# STM32U535 register map
File version: 1.0
CPU: CM33 r0p1, little endian, MPU, FPU, 4 interrupt priority bits
Registers are 32-bit, read-write, reset 0x0 unless marked. A register's access mark holds for its fields unless they carry their own. Offsets are from the block's base; [hi:lo] are bit positions; {n}, {i} and the like mark numbered series.

## TIM15 — General purpose timers
Base 0x40014000
Same registers: SEC_TIM15 0x50014000
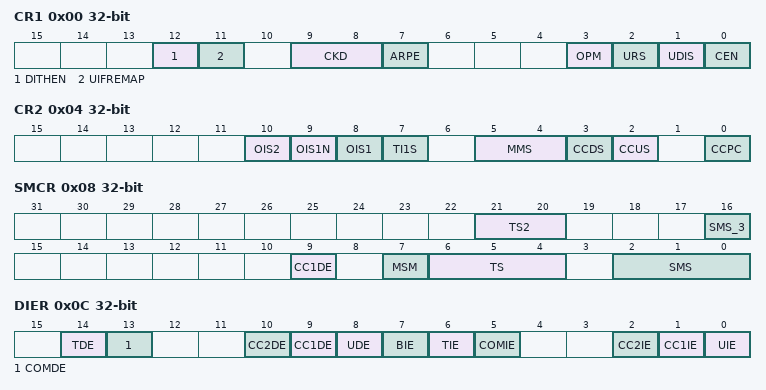
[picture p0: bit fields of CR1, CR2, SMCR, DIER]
0x00 CR1 — control register 1
  [12] DITHEN — Dithering enable
    0=Disabled (Dithering disabled); 1=Enabled (Dithering enabled)
  [11] UIFREMAP — UIF status bit remapping
    0=Disabled (No remapping. UIF status bit is not copied to TIMx_CNT register bit 31); 1=Enabled (Remapping enabled. UIF status bit is copied to TIMx_CNT register bit 31)
  [9:8] CKD — Clock division
    0=Div1 (t_DTS = t_CK_INT); 1=Div2 (t_DTS = 2 × t_CK_INT); 2=Div4 (t_DTS = 4 × t_CK_INT)
  [7] ARPE — Auto-reload preload enable
    0=Disabled (TIMx_APRR register is not buffered); 1=Enabled (TIMx_APRR register is buffered)
  [3] OPM — One-pulse mode
    0=Disabled (Counter is not stopped at update event); 1=Enabled (Counter stops counting at the next update event (clearing the CEN bit))
  [2] URS — Update request source
    0=AnyEvent (Any of counter overflow/underflow, setting UG, or update through slave mode, generates an update interrupt or DMA request); 1=CounterOnly (Only counter overflow/underflow generates an update interrupt or DMA request)
  [1] UDIS — Update disable
    0=Enabled (Update event enabled); 1=Disabled (Update event disabled)
  [0] CEN — Counter enable
    0=Disabled (Counter disabled); 1=Enabled (Counter enabled)
0x04 CR2 — control register 2
  [n+8] OIS{n}N (n=1..1) — Output Idle state (OC{n}N output)
    0=Reset (OCxN=0 after a dead-time when MOE=0); 1=Set (OCxN=1 after a dead-time when MOE=0)
  [2n+6] OIS{n} (n=1..2) — Output Idle state (OC{n} output)
    0=Reset (OCx=0 (after a dead-time if OCx(N) is implemented) when MOE=0); 1=Set (OCx=1 (after a dead-time if OCx(N) is implemented) when MOE=0)
  [7] TI1S — TI1 selection
  [5:4] MMS — Master mode selection
  [3] CCDS — Capture/compare DMA selection
    0=OnCompare (CCx DMA request sent when CCx event occurs); 1=OnUpdate (CCx DMA request sent when update event occurs)
  [2] CCUS — Capture/compare control update selection
    0=Sw (When capture/compare control bits are preloaded (CCPC=1), they are updated by setting the COMG bit only); 1=SwOrEdge (When capture/compare control bits are preloaded (CCPC=1), they are updated by setting the COMG bit or when an rising edge occurs on TRGI)
  [0] CCPC — Capture/compare preloaded control
    0=NotPreloaded (CCxE, CCxNE and OCxM bits are not preloaded); 1=Preloaded (CCxE, CCxNE and OCxM bits are preloaded)
0x08 SMCR — slave mode control register
  [21:20] TS2 — Trigger selection
  [16] SMS_3 — Slave mode selection
  [9] CC1DE — Capture/Compare 1 DMA request enable
  [7] MSM — Master/slave mode
  [6:4] TS — Trigger selection
  [2:0] SMS — Slave mode selection
0x0C DIER — DMA/Interrupt enable register
  [14] TDE — Trigger DMA request enable
    0=Disabled (Trigger DMA request disabled); 1=Enabled (Trigger DMA request enabled)
  [13] COMDE — COM DMA request enable
    0=Disabled (COM DMA request disabled); 1=Enabled (COM DMA request enabled)
  [n+8] CC{n}DE (n=1..2) — Capture/Compare {n} DMA request enable
    0=Disabled (CCx DMA request disabled); 1=Enabled (CCx DMA request enabled)
  [8] UDE — Update DMA request enable
    0=Disabled (Update DMA request disabled); 1=Enabled (Update DMA request enabled)
  [7] BIE — Break interrupt enable
    0=Disabled (Break interrupt disabled); 1=Enabled (Break interrupt enabled)
  [6] TIE — Trigger interrupt enable
    0=Disabled (Trigger interrupt disabled); 1=Enabled (Trigger interrupt enabled)
  [5] COMIE — COM interrupt enable
    0=Disabled (COM interrupt disabled); 1=Enabled (COM interrupt enabled)
  [n] CC{n}IE (n=1..2) — Capture/Compare {n} interrupt enable
    0=Disabled (CCx interrupt disabled); 1=Enabled (CCx interrupt enabled)
  [0] UIE — Update interrupt enable
    0=Disabled (Update interrupt disabled); 1=Enabled (Update interrupt enabled)
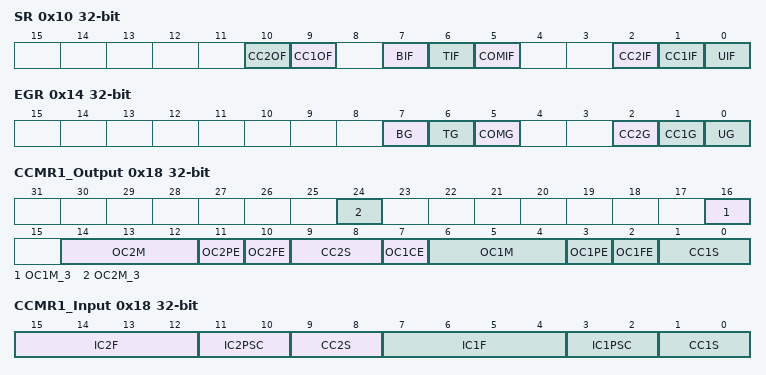
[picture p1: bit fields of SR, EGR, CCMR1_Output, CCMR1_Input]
0x10 SR — status register
  [n+8] CC{n}OF (n=1..2) write-0-clears — Capture/Compare {n} overcapture flag
    on read: 0=No overcapture has been detected; 1=Overcapture (The counter value has been captured in TIMx_CCRx register while CCxIF flag was already set) | on write: 0=Clear flag
  [7] BIF write-0-clears — Break interrupt flag
    on read: 0=NoTrigger (No break event occurred); 1=Trigger (An active level has been detected on the break input. An interrupt is generated if BIE=1 in the TIMx_DIER register) | on write: 0=Clear flag
  [6] TIF write-0-clears — Trigger interrupt flag
    on read: 0=No trigger event occurred; 1=Trigger interrupt pending | on write: 0=Clear flag
  [5] COMIF write-0-clears — COM interrupt flag
    on read: 0=No COM event occurred; 1=COM (COM interrupt pending) | on write: 0=Clear flag
  [n] CC{n}IF (n=1..2) write-0-clears — Capture/compare {n} interrupt flag
    on read: 0=NoMatch (No campture/compare has been detected); 1=Match (If CC1 is an output: The content of the counter TIMx_CNT matches the content of the TIMx_CCR1 register. If CC1 is an input: The counter value has been captured in TIMx_CCR1 register.) | on write: 0=Clear flag
  [0] UIF write-0-clears — Update interrupt flag
    on read: 0=NoUpdateOccurred; 1=UpdatePending (Update interrupt pending) | on write: 0=Clear flag
0x14 EGR access per field — event generation register
  [7] BG wo — Break generation
    1=Trigger (A break event is generated. MOE bit is cleared and BIF flag is set. Related interrupt or DMA transfer can occur if enabled)
  [6] TG wo — Trigger generation
    1=Trigger (The TIF flag is set in TIMx_SR register. Related interrupt or DMA transfer can occur if enabled.)
  [5] COMG rw — Capture/Compare control update generation
    on write: 1=Trigger (When CCPC bit is set, it allows CCxE, CCxNE and OCxM bits to be updated)
  [n] CC{n}G (n=1..2) wo — Capture/compare {n} generation
    1=Trigger (If CC1 is an output: CC1IF flag is set, Corresponding interrupt or DMA request is sent if enabled. If CC1 is an input: The current value of the counter is captured in TIMx_CCR1 register.)
  [0] UG wo — Update generation
    1=Update (Re-initializes the timer counter and generates an update of the registers.)
0x18 CCMR1_Output — capture/compare mode register (output mode)
  [8n+8] OC{n}M_3 (n=1..2) — Output compare {n} mode, bit 3
    0=Normal output compare mode (modes 0-7); 1=Extended output compare mode (modes 7-15)
  [n+6] OC{n}CE (n=1..1) — Output compare {n} clear enable
    0=Disabled (OCxRef is not affected by the ocref_clr_int signal); 1=Enabled (OCxRef is cleared as soon as a High level is detected on ocref_clr_int signal)
  [8n-2:8n-4] OC{n}M (n=1..2) — Output compare {n} mode
    0=Frozen (The comparison between the output compare register TIMx_CCRy and the counter TIMx_CNT has no effect on the outputs / OpmMode1: Retriggerable OPM mode 1 - In up-counting mode, the channel is active until a trigger event is detected (on TRGI signal). In down-counting mode, the channel is inactive); 1=ActiveOnMatch (Set channel to active level on match. OCyREF signal is forced high when the counter matches the capture/compare register / OpmMode2: Inversely to OpmMode1); 2=InactiveOnMatch (Set channel to inactive level on match. OCyREF signal is forced low when the counter matches the capture/compare register / Reserved); 3=Toggle (OCyREF toggles when TIMx_CNT=TIMx_CCRy / Reserved); 4=ForceInactive (OCyREF is forced low / CombinedPwmMode1: OCyREF has the same behavior as in PWM mode 1. OCyREFC is the logical OR between OC1REF and OC2REF); 5=ForceActive (OCyREF is forced high / CombinedPwmMode2: OCyREF has the same behavior as in PWM mode 2. OCyREFC is the logical AND between OC1REF and OC2REF); 6=PwmMode1 (In upcounting, channel is active as long as TIMx_CNT<TIMx_CCRy else inactive. In downcounting, channel is inactive as long as TIMx_CNT>TIMx_CCRy else active / Reserved); 7=PwmMode2 (Inversely to PwmMode1 / Reserved)
  [8n-5] OC{n}PE (n=1..2) — Output compare {n} preload enable
    0=Disabled (Preload register on CCRx disabled. New values written to CCRx are taken into account immediately); 1=Enabled (Preload register on CCRx enabled. Preload value is loaded into active register on each update event)
  [8n-6] OC{n}FE (n=1..2) — Output compare {n} fast enable
    0=Disabled (Fast output disabled); 1=Enabled (Fast output enabled)
  [8n-7:8n-8] CC{n}S (n=1..2) — Capture/Compare {n} selection
    0=Output (CCx channel is configured as output)
0x18 CCMR1_Input (alternate view of CCMR1_Output) — capture/compare mode register 1 (input mode)
  [9:8] CC2S — Capture/Compare 2 selection
    1=TI2 (CC2 channel is configured as input, IC2 is mapped on TI2); 2=TI1 (CC2 channel is configured as input, IC2 is mapped on TI1); 3=TRC (CC2 channel is configured as input, IC2 is mapped on TRC)
  [8n-1:8n-4] IC{n}F (n=1..2) — Input capture {n} filter
    0=No filter, sampling is done at fDTS; 1=FCK_INT_N2 (fSAMPLING=fCK_INT, N=2); 2=FCK_INT_N4 (fSAMPLING=fCK_INT, N=4); 3=FCK_INT_N8 (fSAMPLING=fCK_INT, N=8); 4=FDTS_Div2_N6 (fSAMPLING=fDTS/2, N=6); 5=FDTS_Div2_N8 (fSAMPLING=fDTS/2, N=8); 6=FDTS_Div4_N6 (fSAMPLING=fDTS/4, N=6); 7=FDTS_Div4_N8 (fSAMPLING=fDTS/4, N=8); 8=FDTS_Div8_N6 (fSAMPLING=fDTS/8, N=6); 9=FDTS_Div8_N8 (fSAMPLING=fDTS/8, N=8); 10=FDTS_Div16_N5 (fSAMPLING=fDTS/16, N=5); 11=FDTS_Div16_N6 (fSAMPLING=fDTS/16, N=6); 12=FDTS_Div16_N8 (fSAMPLING=fDTS/16, N=8); 13=FDTS_Div32_N5 (fSAMPLING=fDTS/32, N=5); 14=FDTS_Div32_N6 (fSAMPLING=fDTS/32, N=6); 15=FDTS_Div32_N8 (fSAMPLING=fDTS/32, N=8)
  [8n-5:8n-6] IC{n}PSC (n=1..2) — Input capture {n} prescaler
    0=No prescaler, capture is done each time an edge is detected on the capture input; 1=TwoEvents (Capture is done once every 2 events); 2=FourEvents (Capture is done once every 4 events); 3=EightEvents (Capture is done once every 8 events)
  [1:0] CC1S — Capture/Compare 1 selection
    1=TI1 (CC1 channel is configured as input, IC1 is mapped on TI1); 2=TI2 (CC1 channel is configured as input, IC1 is mapped on TI2); 3=TRC (CC1 channel is configured as input, IC1 is mapped on TRC)
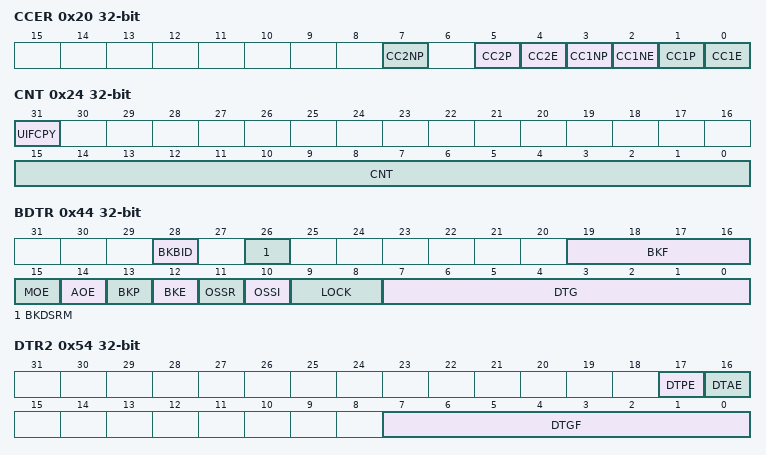
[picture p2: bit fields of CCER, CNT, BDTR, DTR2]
0x20 CCER — capture/compare enable register
  [4n-1] CC{n}NP (n=1..2) — Capture/Compare {n} output Polarity
    0=ActiveHigh (OCxN active high); 1=ActiveLow (OCxN active low)
  [n+1] CC{n}NE (n=1..1) — Capture/Compare {n} complementary output enable
    0=Disabled (Complementary output disabled); 1=Enabled (Complementary output enabled)
  [4n-3] CC{n}P (n=1..2) — Capture/Compare {n} output Polarity
    0=RisingEdge (Noninverted/rising edge); 1=FallingEdge (Inverted/falling edge)
  [4n-4] CC{n}E (n=1..2) — Capture/Compare {n} output enable
    0=Disabled (Capture disabled); 1=Enabled (Capture enabled)
0x24 CNT access per field — counter
  [31] UIFCPY ro — UIF Copy
    0=NoUpdateOccurred; 1=UpdatePending (Update interrupt pending)
  [15:0] CNT rw — counter value
0x28 PSC — prescaler
  [15:0] PSC — Prescaler value
0x2C ARR reset 0xFFFF — auto-reload register
  [19:0] ARR — Auto-reload value
0x30 RCR — repetition counter register
  [7:0] REP — Repetition counter value
{0x30+4i} CCR{i} (i=1..2) — capture/compare register
  [19:0] CCR — Capture/Compare value
0x44 BDTR — break and dead-time register
  [28] BKBID — Break Bidirectional
  [26] BKDSRM — Break Disarm
  [19:16] BKF — Break filter
  [15] MOE — Main output enable
    0=DisabledIdle (OC/OCN are disabled or forced idle depending on OSSI); 1=Enabled (OC/OCN are enabled if CCxE/CCxNE are set)
  [14] AOE — Automatic output enable
    0=Manual (MOE can be set only by software); 1=Automatic (MOE can be set by software or automatically at the next update event (if none of the break inputs BRK and BRK2 is active))
  [13] BKP — Break polarity
    0=ActiveLow (Break input BRKx is active low); 1=ActiveHigh (Break input BRKx is active high)
  [12] BKE — Break enable
    0=Disabled (Break function x disabled); 1=Enabled (Break function x enabled)
  [11] OSSR — Off-state selection for Run mode
    0=HiZ (When inactive, OC/OCN outputs are disabled); 1=IdleLevel (When inactive, OC/OCN outputs are enabled with their inactive level)
  [10] OSSI — Off-state selection for Idle mode
    0=HiZ (When inactive, OC/OCN outputs are disabled); 1=IdleLevel (When inactive, OC/OCN outputs are forced to idle level)
  [9:8] LOCK — Lock configuration
    0=Off (No bit is write protected); 1=Level1 (Any bits except MOE, OSSR, OSSI and LOCK in TIMx_BDTR register, OISx and OISxN bits in TIMx_CR2 register can no longer be written); 2=Level2 (LOCK Level 1 + CC Polarity bits (CCxP/CCxNP bits in TIMx_CCER register, as long as the related channel is configured in output through the CCxS bits) as well as OSSR and OSSI bits can no longer be written); 3=Level3 (LOCK Level 2 + CC Control bits (OCxM and OCxPE bits in TIMx_CCMRx registers, as long as the related channel is configured in output through the CCxS bits) can no longer be written)
  [7:0] DTG — Dead-time generator setup
0x54 DTR2 — timer deadtime register 2
  [17] DTPE — Deadtime preload enable
  [16] DTAE — Deadtime asymmetric enable
  [7:0] DTGF — Dead-time falling edge generator setup
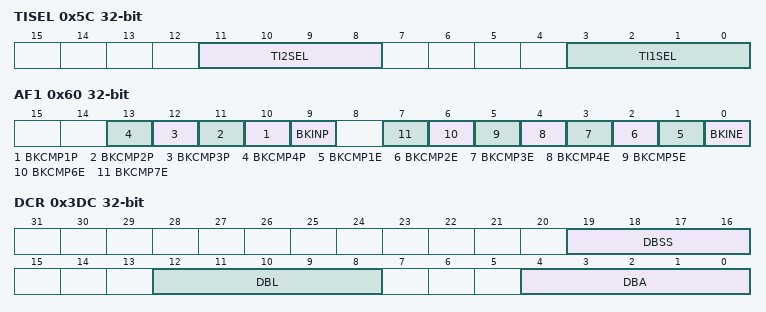
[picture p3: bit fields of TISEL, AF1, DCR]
0x5C TISEL — input selection register
  [11:8] TI2SEL — selects tim_ti2_in[0..15] input
  [3:0] TI1SEL — selects tim_ti1_in[0..15] input
0x60 AF1 — alternate function register 1
  [n+9] BKCMP{n}P (n=1..4) — tim_brk_cmp{n} input polarity
  [9] BKINP — TIMx_BKIN input polarity
  [n] BKCMP{n}E (n=1..7) — tim_brk_cmp{n} enable
  [0] BKINE — TIMx_BKIN input enable
0x64 AF2 reset 0x1 — alternate function register 2
  [18:16] OCRSEL — ocref_clr source selection
0x3DC DCR — DMA control register
  [19:16] DBSS — DMA burst source selection
  [12:8] DBL — DMA burst length
  [4:0] DBA — DMA base address
0x3E0 DMAR — DMA address for full transfer
  [31:0] DMAB — DMA register for burst accesses
